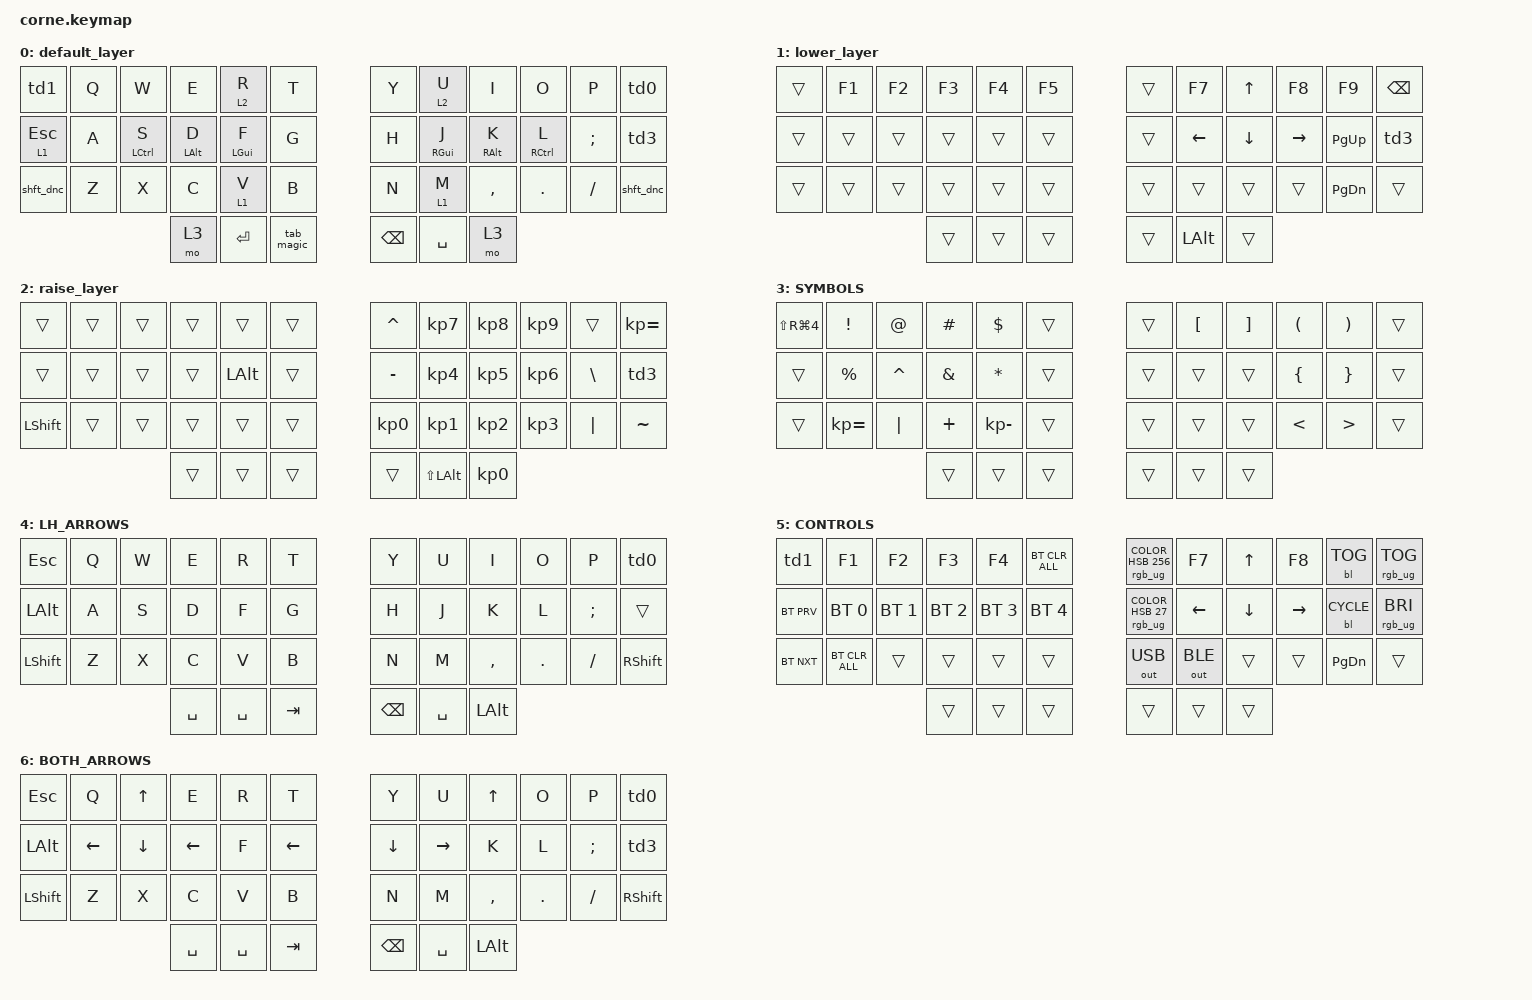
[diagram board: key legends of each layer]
/*
 * Copyright (c) 2020 The ZMK Contributors
 *
 * SPDX-License-Identifier: MIT
 */

#include <behaviors.dtsi>
#include <dt-bindings/zmk/bt.h>
#include <dt-bindings/zmk/keys.h>
#include <dt-bindings/zmk/rgb.h>
#include <dt-bindings/zmk/backlight.h>
#include "zmk-helpers/helper.h"
#include <dt-bindings/zmk/outputs.h>

// Source desired key-position labels
#include "zmk-helpers/key-labels/42.h"

#define KEYS_L LT0 LT1 LT2 LT3 LT4 LT5 LM0 LM1 LM2 LM3 LM4 LM5 LB0 LB1 LB2 LB3 LB4 LB5// left hand
#define KEYS_R RT0 RT1 RT2 RT3 RT4 RT5 RM0 RM1 RM2 RM3 RM4 RM5 RB0 RB1 RB2 RB3 RB4 RB5// right hand
#define THUMBS LH2 LH1 LH0 RH0 RH1 RH2                                      // thumbs

#define HM_TAPPING_TERM 300
#define HM_TAPPING_TERM_FAST 150
#define HM_PRIOR_IDLE 25

&mt {tapping-term-ms = <300>;};
/{
    macros {
        opt_hld: opt_hld {
            compatible = "zmk,behavior-macro";
            #binding-cells = <0>;
            bindings
                = <&macro_press &mo 6 &kp LALT>
                , <&macro_pause_for_release>
                , <&macro_release &mo 6 &kp LS(LG(LCTRL))>
                ;
        };
    };
};    
/{
    behaviors {
        td0: tap_dance_0 {
            compatible = "zmk,behavior-tap-dance";
            #binding-cells = <0>;
            tapping-term-ms = <200>;
            bindings = <&kp MINUS>, <&tog 4>;
        };
        td1: tap_dance_1 {
            compatible = "zmk,behavior-tap-dance";
            #binding-cells = <0>;
            tapping-term-ms = <200>;
            bindings = <&kp DEL>, <&tog 5>;
        };
        td2: tap_dance_2 {
            compatible = "zmk,behavior-tap-dance";
            #binding-cells = <0>;
            tapping-term-ms = <200>;
            bindings = <&kp RET>, <&kp Q>;
        };
         td3: tap_dance_3 {
            compatible = "zmk,behavior-tap-dance";
            #binding-cells = <0>;
            tapping-term-ms = <200>;
            bindings = <&kp SQT>, <&tog 1>;
        };
        shft_dnc: shift_dance {
            compatible = "zmk,behavior-tap-dance";
            #binding-cells = <0>;
            tapping-term-ms = <200>;
            bindings = <&kp LEFT_SHIFT>, <&caps_word>;
        };
        tab_magic: tab_magic {
            compatible = "zmk,behavior-tap-dance";
            #binding-cells = <0>;
            tapping-term-ms = <200>;
            bindings = <&kp TAB>, <&kp LS(LG(LCTRL))>;
        };
        hm_l: homerow_mods_left {
            compatible = "zmk,behavior-hold-tap";
            #binding-cells = <2>;
            bindings = <&kp>,  <&kp>;
            flavor = "balanced";
            tapping-term-ms = <300>;
            quick-tap-ms = <175>;               
            require-prior-idle-ms = <HM_PRIOR_IDLE>;
            hold-trigger-key-positions = <KEYS_L THUMBS>;
            hold-trigger-on-release;
        };
        hm_r: homerow_mods_right {
            compatible = "zmk,behavior-hold-tap";
            #binding-cells = <2>;
            bindings = <&kp>, <&kp>;
            flavor = "balanced";
            tapping-term-ms = <HM_TAPPING_TERM>;
            quick-tap-ms = <175>;
            require-prior-idle-ms = <HM_PRIOR_IDLE>;
            hold-trigger-key-positions = <KEYS_R THUMBS>;
            hold-trigger-on-release;
        };
    };
};
/ {
    keymap {
        compatible = "zmk,keymap";

        default_layer {
            // -----------------------------------------------------------------------------------------
            // |  TAB |  Q  |  W  |  E  |  R  |  T  |   |  Y  |  U   |  I  |  O  |  P  | BKSP |
            // | CTRL |  A  |  S  |  D  |  F  |  G  |   |  H  |  J   |  K  |  L  |  ;  |  '   |
            // | SHFT |  Z  |  X  |  C  |  V  |  B  |   |  N  |  M   |  ,  |  .  |  /  | ESC  |
            //                    | GUI | LWR | SPC |   | ENT | RSE  | ALT |

            bindings = <
&td1  &kp Q  &kp W        &kp E       &lt 2 R     &kp T      &kp Y          &lt 2 U     &kp I       &kp O        &kp P     &td0
&lt 1 ESCAPE  &kp A  &hm_l LCTRL S  &hm_l LALT D  &hm_l LGUI F  &kp G      &kp H          &hm_r RGUI J  &hm_r RALT K  &hm_r RCTRL L  &kp SEMI  &td3
&shft_dnc     &kp Z  &kp X        &kp C       &lt 1 V     &kp B      &kp N          &lt 1 M     &kp COMMA   &kp DOT &kp FSLH  &shft_dnc
                                  &mo 3       &kp RET      &tab_magic   &kp BACKSPACE  &kp SPACE   &mo 3
            >;
        };

        lower_layer {
            // -----------------------------------------------------------------------------------------
            // |  TAB |  1  |  2  |  3  |  4  |  5  |   |  6  |  7  |  8  |  9  |  0  | BKSP |
            // | BTCLR| BT1 | BT2 | BT3 | BT4 | BT5 |   | LFT | DWN |  UP | RGT |     |      |
            // | SHFT |     |     |     |     |     |   |     |     |     |     |     |      |
            //                    | GUI |     | SPC |   | ENT |     | ALT |

            bindings = <
&trans     &kp F1      &kp F2    &kp F3        &kp F4        &kp F5          &trans  &kp F7    &kp UP_ARROW  &kp F8     &kp F9         &kp BSPC
&trans     &trans      &trans    &trans        &trans        &trans          &trans  &kp LEFT  &kp DOWN      &kp RIGHT  &kp PG_UP      &td3
&trans     &trans      &trans    &trans        &trans        &trans          &trans  &trans    &trans        &trans    &kp PAGE_DOWN  &trans
                                         &trans        &trans        &trans          &trans  &kp LALT    &trans
            >;
        };
        
        raise_layer {
            // -----------------------------------------------------------------------------------------
            // |  TAB |  !  |  @  |  #  |  $  |  %  |   |  ^  |  &  |  *  |  (  |  )  | BKSP |
            // | CTRL |     |     |     |     |     |   |  -  |  =  |  [  |  ]  |  \  |  `   |
            // | SHFT |     |     |     |     |     |   |  _  |  +  |  {  |  }  | "|" |  ~   |
            //                    | GUI |     | SPC |   | ENT |     | ALT |

            bindings = <
&trans     &trans  &trans  &trans  &trans  &trans    &kp CARET        &kp KP_NUMBER_7  &kp KP_NUMBER_8  &kp KP_NUMBER_9  &trans    &kp KP_EQUAL
&trans     &trans  &trans  &trans  &kp LALT &trans    &kp MINUS        &kp KP_NUMBER_4  &kp KP_NUMBER_5  &kp KP_NUMBER_6  &kp BSLH  &td3
&kp LSHFT  &trans  &trans  &trans  &trans  &trans    &kp KP_NUMBER_0  &kp KP_NUMBER_1  &kp KP_NUMBER_2  &kp KP_NUMBER_3  &kp PIPE  &kp TILDE
                           &trans  &trans  &trans    &trans           &kp LS(LALT)         &kp KP_NUMBER_0
            >;
        };

        SYMBOLS {
            bindings = <
&kp LS(RG(NUMBER_4)) &kp EXCL      &kp AT_SIGN  &kp HASH       &kp DOLLAR    &trans    &trans  &kp LEFT_BRACKET  &kp RIGHT_BRACKET  &kp LEFT_PARENTHESIS  &kp RIGHT_PARENTHESIS  &trans
&trans  &kp PERCENT   &kp CARET    &kp AMPERSAND  &kp ASTERISK  &trans    &trans  &trans            &trans             &kp LEFT_BRACE        &kp RIGHT_BRACE        &trans
&trans  &kp KP_EQUAL  &kp PIPE     &kp PLUS       &kp KP_MINUS  &trans    &trans  &trans            &trans             &kp LESS_THAN         &kp GREATER_THAN       &trans
                                   &trans         &trans        &trans    &trans  &trans            &trans
            >;
        };

        LH_ARROWS {    
            bindings = <
&kp ESC       &kp Q          &kp W         &kp E     &kp R     &kp T      &kp Y     &kp U     &kp I     &kp O      &kp P     &td0
&kp LALT      &kp A          &kp S         &kp D     &kp F     &kp G     &kp H      &kp J     &kp K     &kp L     &kp SEMI   &trans
&kp LSHIFT    &kp Z          &kp X         &kp C     &kp V     &kp B      &kp N     &kp M     &kp COMMA &kp DOT   &kp SLASH &kp RSHIFT
                                       &kp SPACE     &kp SPACE &kp TAB &kp BSPC &kp SPC &kp LALT
            >;
        };
    CONTROLS {
            bindings = <
&td1           &kp F1          &kp F2        &kp F3        &kp F4        &bt BT_CLR_ALL  &rgb_ug RGB_COLOR_HSB (256,4,100) &kp F7       &kp UP_ARROW  &kp F8        &bl BL_TOG         &rgb_ug RGB_TOG
&bt BT_PRV     &bt BT_SEL 0    &bt BT_SEL 1  &bt BT_SEL 2  &bt BT_SEL 3  &bt BT_SEL 4    &rgb_ug RGB_COLOR_HSB (27,32,100) &kp LEFT     &kp DOWN      &kp RIGHT     &bl BL_CYCLE      &rgb_ug RGB_BRI
&bt BT_NXT     &bt BT_CLR_ALL  &trans        &trans        &trans        &trans          &out OUT_USB                      &out OUT_BLE &trans        &trans        &kp PAGE_DOWN     &trans
                                         &trans        &trans        &trans          &trans  &trans    &trans
            >;
        };
    BOTH_ARROWS {
            bindings = <
&kp ESC       &kp Q          &kp UP_ARROW         &kp E     &kp R     &kp T      &kp Y     &kp U     &kp UP_ARROW     &kp O      &kp P     &td0
&kp LALT      &kp LEFT_ARROW          &kp DOWN_ARROW         &kp LEFT_ARROW     &kp F     &kp LEFT_ARROW     &kp DOWN_ARROW      &kp RIGHT_ARROW     &kp K     &kp L     &kp SEMI   &td3
&kp LSHIFT    &kp Z          &kp X         &kp C     &kp V     &kp B      &kp N     &kp M     &kp COMMA &kp DOT   &kp SLASH &kp RSHIFT
                                       &kp SPACE     &kp SPACE &kp TAB &kp BSPC &kp SPC &kp LALT
            >;
        };
    };
};
